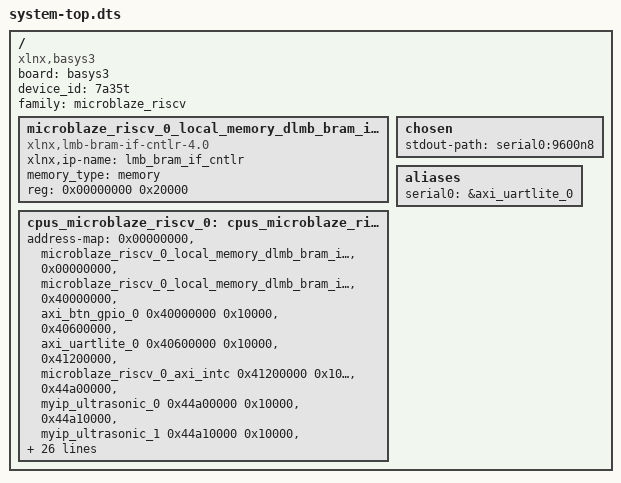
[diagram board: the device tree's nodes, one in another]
/dts-v1/;
#include "pl.dtsi"
/ {
	board = "basys3";
	compatible = "xlnx,basys3";
	device_id = "7a35t";
	#address-cells = <1>;
	#size-cells = <1>;
	family = "microblaze_riscv";
	microblaze_riscv_0_local_memory_dlmb_bram_if_cntlr_memory: memory@0 {
		compatible = "xlnx,lmb-bram-if-cntlr-4.0";
		xlnx,ip-name = "lmb_bram_if_cntlr";
		device_type = "memory";
		memory_type = "memory";
		reg = <0x00000000 0x20000>;
	};
	chosen {
		stdout-path = "serial0:9600n8";
	};
	aliases {
		serial0 = &axi_uartlite_0;
	};
	cpus_microblaze_riscv_0: cpus_microblaze_riscv@0 {
		address-map = <0x00000000 &microblaze_riscv_0_local_memory_dlmb_bram_if_cntlr_memory 0x00000000 0x20000>, 
			      <0x00000000 &microblaze_riscv_0_local_memory_dlmb_bram_if_cntlr 0x00000000 0x20000>, 
			      <0x40000000 &axi_btn_gpio_0 0x40000000 0x10000>, 
			      <0x40600000 &axi_uartlite_0 0x40600000 0x10000>, 
			      <0x41200000 &microblaze_riscv_0_axi_intc 0x41200000 0x10000>, 
			      <0x44a00000 &myip_ultrasonic_0 0x44a00000 0x10000>, 
			      <0x44a10000 &myip_ultrasonic_1 0x44a10000 0x10000>, 
			      <0x44a20000 &myip_rtc_read_0 0x44a20000 0x10000>, 
			      <0x44a30000 &myip_dht11_0 0x44a30000 0x10000>, 
			      <0x44a40000 &myip_sensor_adc_0 0x44a40000 0x10000>, 
			      <0x44a50000 &myip_sensor_dgt_0 0x44a50000 0x10000>, 
			      <0x44a60000 &myip_stepper_0 0x44a60000 0x10000>, 
			      <0x44a70000 &myip_fan_0 0x44a70000 0x10000>, 
			      <0x44a80000 &myip_iic_txtlcd_0 0x44a80000 0x10000>, 
			      <0x44a90000 &myip_servo180_0 0x44a90000 0x10000>, 
			      <0x44aa0000 &myip_servo180_1 0x44aa0000 0x10000>, 
			      <0x44ab0000 &myip_servo180_2 0x44ab0000 0x10000>, 
			      <0x44ac0000 &myip_servo180_3 0x44ac0000 0x10000>, 
			      <0x44ad0000 &myip_servo180_4 0x44ad0000 0x10000>, 
			      <0x44ae0000 &myip_servo180_5 0x44ae0000 0x10000>, 
			      <0x44af0000 &myip_servo180_6 0x44af0000 0x10000>;
		#ranges-address-cells = <0x1>;
		#ranges-size-cells = <0x1>;
	};
};
